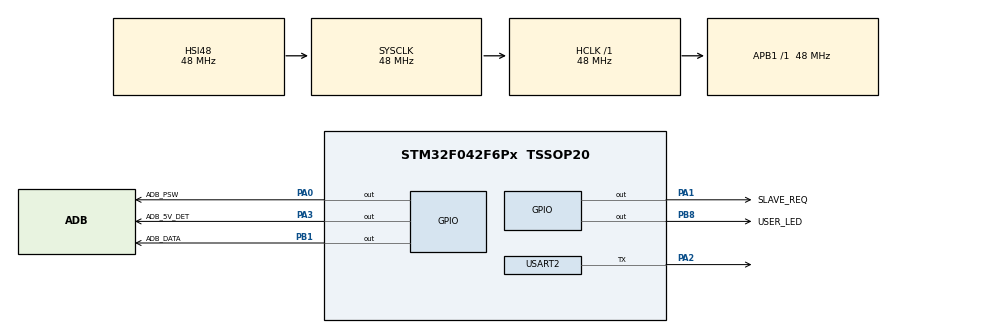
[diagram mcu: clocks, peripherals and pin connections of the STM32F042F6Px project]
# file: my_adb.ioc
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Mcu.Family=STM32F0
Mcu.Name=STM32F042F6Px
Mcu.Package=TSSOP20
PA0.GPIO_Label=ADB_PSW
PA0.GPIO_ModeDefaultOutputPP=GPIO_MODE_OUTPUT_OD
PA0.PinState=GPIO_PIN_SET
PA0.Signal=GPIO_Output
PA1.GPIO_Label=SLAVE_REQ
PA1.GPIO_ModeDefaultOutputPP=GPIO_MODE_OUTPUT_PP
PA1.PinState=GPIO_PIN_SET
PA1.Signal=GPIO_Output
PA13.Mode=Serial_Wire
PA13.Signal=SYS_SWDIO
PA14.Mode=Serial_Wire
PA14.Signal=SYS_SWCLK
PA2.Mode=Half_duplex(single_wire_mode)
PA2.Signal=USART2_TX
PA3.GPIO_Label=ADB_5V_DET
PA3.PinState=GPIO_PIN_SET
PA3.Signal=GPIO_Output
PB1.GPIO_Label=ADB_DATA
PB1.GPIO_ModeDefaultOutputPP=GPIO_MODE_OUTPUT_PP
PB1.PinState=GPIO_PIN_SET
PB1.Signal=GPIO_Output
PB8.GPIO_Label=USER_LED
PB8.PinState=GPIO_PIN_SET
PB8.Signal=GPIO_Output
ProjectManager.HeapSize=0x200
ProjectManager.StackSize=0x400
ProjectManager.TargetToolchain=MDK-ARM V5
RCC.AHBFreq_Value=48000000
RCC.APB1Freq_Value=48000000
RCC.APB1TimFreq_Value=48000000
RCC.HCLKFreq_Value=48000000
RCC.I2c1ClockSelection=RCC_I2C1CLKSOURCE_SYSCLK
RCC.SYSCLKFreq_VALUE=48000000
RCC.SYSCLKSource=RCC_SYSCLKSOURCE_HSI48
TIM2.Period=4294967295
TIM2.Prescaler=47
USART2.BaudRate=115200
USART2.Mode=MODE_TX
USART2.VirtualMode-Half_duplex(single_wire_mode)=VM_ASYNC
VP_SYS_VS_PINREMAP.Mode=PINREMAP
VP_TIM2_VS_ClockSourceINT.Mode=Internal
board=custom

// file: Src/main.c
/**
  ******************************************************************************
  * @file           : main.c
  * @brief          : Main program body
  ******************************************************************************
  ** This notice applies to any and all portions of this file
  * that are not between comment pairs USER CODE BEGIN and
  * USER CODE END. Other portions of this file, whether
  * inserted by the user or by software development tools
  * are owned by their respective copyright owners.
  *
  * COPYRIGHT(c) 2022 STMicroelectronics
  *
  * Redistribution and use in source and binary forms, with or without modification,
  * are permitted provided that the following conditions are met:
  *   1. Redistributions of source code must retain the above copyright notice,
  *      this list of conditions and the following disclaimer.
  *   2. Redistributions in binary form must reproduce the above copyright notice,
  *      this list of conditions and the following disclaimer in the documentation
  *      and/or other materials provided with the distribution.
  *   3. Neither the name of STMicroelectronics nor the names of its contributors
  *      may be used to endorse or promote products derived from this software
  *      without specific prior written permission.
  *
  * THIS SOFTWARE IS PROVIDED BY THE COPYRIGHT HOLDERS AND CONTRIBUTORS "AS IS"
  * AND ANY EXPRESS OR IMPLIED WARRANTIES, INCLUDING, BUT NOT LIMITED TO, THE
  * IMPLIED WARRANTIES OF MERCHANTABILITY AND FITNESS FOR A PARTICULAR PURPOSE ARE
  * DISCLAIMED. IN NO EVENT SHALL THE COPYRIGHT HOLDER OR CONTRIBUTORS BE LIABLE
  * FOR ANY DIRECT, INDIRECT, INCIDENTAL, SPECIAL, EXEMPLARY, OR CONSEQUENTIAL
  * DAMAGES (INCLUDING, BUT NOT LIMITED TO, PROCUREMENT OF SUBSTITUTE GOODS OR
  * SERVICES; LOSS OF USE, DATA, OR PROFITS; OR BUSINESS INTERRUPTION) HOWEVER
  * CAUSED AND ON ANY THEORY OF LIABILITY, WHETHER IN CONTRACT, STRICT LIABILITY,
  * OR TORT (INCLUDING NEGLIGENCE OR OTHERWISE) ARISING IN ANY WAY OUT OF THE USE
  * OF THIS SOFTWARE, EVEN IF ADVISED OF THE POSSIBILITY OF SUCH DAMAGE.
  *
  ******************************************************************************
  */
#include "main.h"
#include "stm32f0xx_hal.h"

/* USER CODE BEGIN Includes */
#include <string.h>
#include <stdlib.h>
#include "shared.h"

/* USER CODE END Includes */

TIM_HandleTypeDef htim2;

UART_HandleTypeDef huart2;

/* USER CODE BEGIN PV */
/* Private variables ---------------------------------------------------------*/

/* USER CODE END PV */

void SystemClock_Config(void);
static void MX_GPIO_Init(void);
static void MX_USART2_UART_Init(void);
static void MX_TIM2_Init(void);

/* USER CODE BEGIN PFP */
/* Private function prototypes -----------------------------------------------*/

/* USER CODE END PFP */

/* USER CODE BEGIN 0 */
int fputc(int ch, FILE *f)
{
    HAL_UART_Transmit(&huart2, (unsigned char *)&ch, 1, 10);
    return ch;
}

/* USER CODE END 0 */

int main(void)
{

  /* MCU Configuration----------------------------------------------------------*/

  /* Reset of all peripherals, Initializes the Flash interface and the Systick. */
  HAL_Init();

  /* Configure the system clock */
  SystemClock_Config();

  /* Initialize all configured peripherals */
  MX_GPIO_Init();
  MX_USART2_UART_Init();
  MX_TIM2_Init();

  /* Infinite loop */
  while (1)
  {

  /* USER CODE BEGIN 3 */
    HAL_GPIO_TogglePin(USER_LED_GPIO_Port, USER_LED_Pin);
    HAL_GPIO_TogglePin(ADB_PSW_GPIO_Port, ADB_PSW_Pin);
    HAL_GPIO_TogglePin(SLAVE_REQ_GPIO_Port, SLAVE_REQ_Pin);
    HAL_GPIO_TogglePin(ADB_5V_DET_GPIO_Port, ADB_5V_DET_Pin);
    HAL_GPIO_TogglePin(ADB_DATA_GPIO_Port, ADB_DATA_Pin);
    HAL_Delay(250);
  }
  /* USER CODE END 3 */

}

void SystemClock_Config(void)
{

  RCC_OscInitTypeDef RCC_OscInitStruct;
  RCC_ClkInitTypeDef RCC_ClkInitStruct;

    /**Initializes the CPU, AHB and APB busses clocks
    */
  RCC_OscInitStruct.OscillatorType = RCC_OSCILLATORTYPE_HSI48;
  RCC_OscInitStruct.HSI48State = RCC_HSI48_ON;
  RCC_OscInitStruct.PLL.PLLState = RCC_PLL_NONE;
  if (HAL_RCC_OscConfig(&RCC_OscInitStruct) != HAL_OK)
  {
    _Error_Handler(__FILE__, __LINE__);
  }

    /**Initializes the CPU, AHB and APB busses clocks
    */
  RCC_ClkInitStruct.ClockType = RCC_CLOCKTYPE_HCLK|RCC_CLOCKTYPE_SYSCLK
                              |RCC_CLOCKTYPE_PCLK1;
  RCC_ClkInitStruct.SYSCLKSource = RCC_SYSCLKSOURCE_HSI48;
  RCC_ClkInitStruct.AHBCLKDivider = RCC_SYSCLK_DIV1;
  RCC_ClkInitStruct.APB1CLKDivider = RCC_HCLK_DIV1;

  if (HAL_RCC_ClockConfig(&RCC_ClkInitStruct, FLASH_LATENCY_1) != HAL_OK)
  {
    _Error_Handler(__FILE__, __LINE__);
  }

    /**Configure the Systick interrupt time
    */
  HAL_SYSTICK_Config(HAL_RCC_GetHCLKFreq()/1000);

    /**Configure the Systick
    */
  HAL_SYSTICK_CLKSourceConfig(SYSTICK_CLKSOURCE_HCLK);

  /* SysTick_IRQn interrupt configuration */
  HAL_NVIC_SetPriority(SysTick_IRQn, 0, 0);
}

/* TIM2 init function */
static void MX_TIM2_Init(void)
{

  TIM_ClockConfigTypeDef sClockSourceConfig;
  TIM_MasterConfigTypeDef sMasterConfig;

  htim2.Instance = TIM2;
  htim2.Init.Prescaler = 47;
  htim2.Init.CounterMode = TIM_COUNTERMODE_UP;
  htim2.Init.Period = 4294967295;
  htim2.Init.ClockDivision = TIM_CLOCKDIVISION_DIV1;
  htim2.Init.AutoReloadPreload = TIM_AUTORELOAD_PRELOAD_DISABLE;
  if (HAL_TIM_Base_Init(&htim2) != HAL_OK)
  {
    _Error_Handler(__FILE__, __LINE__);
  }

  sClockSourceConfig.ClockSource = TIM_CLOCKSOURCE_INTERNAL;
  if (HAL_TIM_ConfigClockSource(&htim2, &sClockSourceConfig) != HAL_OK)
  {
    _Error_Handler(__FILE__, __LINE__);
  }

  sMasterConfig.MasterOutputTrigger = TIM_TRGO_RESET;
  sMasterConfig.MasterSlaveMode = TIM_MASTERSLAVEMODE_DISABLE;
  if (HAL_TIMEx_MasterConfigSynchronization(&htim2, &sMasterConfig) != HAL_OK)
  {
    _Error_Handler(__FILE__, __LINE__);
  }

}

/* USART2 init function */
static void MX_USART2_UART_Init(void)
{

  huart2.Instance = USART2;
  huart2.Init.BaudRate = 115200;
  huart2.Init.WordLength = UART_WORDLENGTH_8B;
  huart2.Init.StopBits = UART_STOPBITS_1;
  huart2.Init.Parity = UART_PARITY_NONE;
  huart2.Init.Mode = UART_MODE_TX;
  huart2.Init.HwFlowCtl = UART_HWCONTROL_NONE;
  huart2.Init.OverSampling = UART_OVERSAMPLING_16;
  huart2.Init.OneBitSampling = UART_ONE_BIT_SAMPLE_DISABLE;
  huart2.AdvancedInit.AdvFeatureInit = UART_ADVFEATURE_NO_INIT;
  if (HAL_HalfDuplex_Init(&huart2) != HAL_OK)
  {
    _Error_Handler(__FILE__, __LINE__);
  }

}

/** Configure pins as
        * Analog
        * Input
        * Output
        * EVENT_OUT
        * EXTI
*/
static void MX_GPIO_Init(void)
{

  GPIO_InitTypeDef GPIO_InitStruct;

  /* GPIO Ports Clock Enable */
  __HAL_RCC_GPIOB_CLK_ENABLE();
  __HAL_RCC_GPIOA_CLK_ENABLE();

  /*Configure GPIO pin Output Level */
  HAL_GPIO_WritePin(GPIOB, USER_LED_Pin|ADB_DATA_Pin, GPIO_PIN_SET);

  /*Configure GPIO pin Output Level */
  HAL_GPIO_WritePin(GPIOA, ADB_PSW_Pin|SLAVE_REQ_Pin|ADB_5V_DET_Pin, GPIO_PIN_SET);

  /*Configure GPIO pins : USER_LED_Pin ADB_DATA_Pin */
  GPIO_InitStruct.Pin = USER_LED_Pin|ADB_DATA_Pin;
  GPIO_InitStruct.Mode = GPIO_MODE_OUTPUT_PP;
  GPIO_InitStruct.Pull = GPIO_NOPULL;
  GPIO_InitStruct.Speed = GPIO_SPEED_FREQ_LOW;
  HAL_GPIO_Init(GPIOB, &GPIO_InitStruct);

  /*Configure GPIO pin : ADB_PSW_Pin */
  GPIO_InitStruct.Pin = ADB_PSW_Pin;
  GPIO_InitStruct.Mode = GPIO_MODE_OUTPUT_OD;
  GPIO_InitStruct.Pull = GPIO_NOPULL;
  GPIO_InitStruct.Speed = GPIO_SPEED_FREQ_LOW;
  HAL_GPIO_Init(ADB_PSW_GPIO_Port, &GPIO_InitStruct);

  /*Configure GPIO pins : SLAVE_REQ_Pin ADB_5V_DET_Pin */
  GPIO_InitStruct.Pin = SLAVE_REQ_Pin|ADB_5V_DET_Pin;
  GPIO_InitStruct.Mode = GPIO_MODE_OUTPUT_PP;
  GPIO_InitStruct.Pull = GPIO_NOPULL;
  GPIO_InitStruct.Speed = GPIO_SPEED_FREQ_LOW;
  HAL_GPIO_Init(GPIOA, &GPIO_InitStruct);

}

void _Error_Handler(char *file, int line)
{
  while(1)
  {
  }
}

/************************ (C) COPYRIGHT STMicroelectronics *****END OF FILE****/
